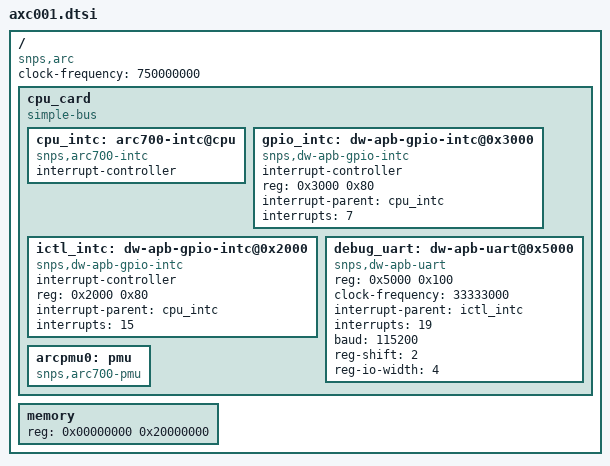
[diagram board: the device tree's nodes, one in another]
/*
 * Copyright (C) 2013, 2014 Synopsys, Inc. (www.synopsys.com)
 *
 * This program is free software; you can redistribute it and/or modify
 * it under the terms of the GNU General Public License version 2 as
 * published by the Free Software Foundation.
 */

/*
 * Device tree for AXC001 770D/EM6/AS221 CPU card
 * Note that this file only supports the 770D CPU
 */

/ {
	compatible = "snps,arc";
	clock-frequency = <750000000>;	/* 750 MHZ */
	#address-cells = <1>;
	#size-cells = <1>;

	cpu_card {
		compatible = "simple-bus";
		#address-cells = <1>;
		#size-cells = <1>;

		ranges = <0x00000000 0xf0000000 0x10000000>;

		cpu_intc: arc700-intc@cpu {
			compatible = "snps,arc700-intc";
			interrupt-controller;
			#interrupt-cells = <1>;
		};

		/*
		 * this GPIO intc simply acts as a "wire" for connecting
		 * ARC core intc to main board intc (mb_intc in axs10x_mb.dtsi)
		 * which in turn connects to mb peripherals (eth, UART, ...)
		 */
		gpio_intc: dw-apb-gpio-intc@0x3000 {
			compatible = "snps,dw-apb-gpio-intc";
			interrupt-controller;
			reg = < 0x3000 0x80 >;
			#interrupt-cells = <1>;
			interrupt-parent = <&cpu_intc>;
			interrupts = < 7 >;
		};

		/*
		 * this GPIO block ORs all interrupts on CPU card (creg,..)
		 * to uplink only 1 IRQ to ARC core intc
		 */
		ictl_intc: dw-apb-gpio-intc@0x2000 {
			compatible = "snps,dw-apb-gpio-intc";
			interrupt-controller;
			reg = < 0x2000 0x80 >;
			#interrupt-cells = <1>;
			interrupt-parent = <&cpu_intc>;
			interrupts = <15>;
		};

		debug_uart: dw-apb-uart@0x5000 {
			compatible = "snps,dw-apb-uart";
			reg = <0x5000 0x100>;
			clock-frequency = <33333000>;
			interrupt-parent = <&ictl_intc>;
			interrupts = <19>;
			baud = <115200>;
			reg-shift = <2>;
			reg-io-width = <4>;
		};

		arcpmu0: pmu {
			compatible = "snps,arc700-pmu";
		};
	};

	memory {
		#address-cells = <1>;
		#size-cells = <1>;
		ranges = <0x00000000 0x80000000 0x40000000>;
		device_type = "memory";
		reg = <0x00000000 0x20000000>;	/* 512MiB */
	};
};
